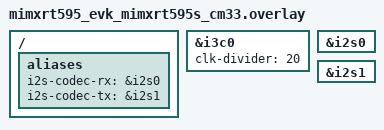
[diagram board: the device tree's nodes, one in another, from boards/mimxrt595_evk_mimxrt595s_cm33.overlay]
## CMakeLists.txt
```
# SPDX-License-Identifier: Apache-2.0

cmake_minimum_required(VERSION 3.20.0)

find_package(Zephyr REQUIRED HINTS $ENV{ZEPHYR_BASE})
project(midi_synth)

target_sources(app PRIVATE src/main.c)
```

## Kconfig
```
# Copyright (c) 2025 NXP
# SPDX-License-Identifier: Apache-2.0

source "Kconfig.zephyr"

config I2S_INIT_BUFFERS
	int "Initial count of audio data blocks"
	default 2
	help
	  Controls the initial count of audio data blocks, which are (optionally)
	  filled by data from the DMIC peripheral and played back by the I2S
	  output peripheral.

config SAMPLE_FREQ
	int "Sample rate"
	default 48000
	help
	  Sample frequency of the system.
```

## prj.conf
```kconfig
CONFIG_I2S=y
CONFIG_AUDIO=y
CONFIG_AUDIO_DMIC=n
```

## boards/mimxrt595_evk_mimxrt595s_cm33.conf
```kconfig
#
# Copyright 2024 NXP
#
# SPDX-License-Identifier: Apache-2.0
#

CONFIG_DMA=y
CONFIG_I2S_MCUX_FLEXCOMM=y
CONFIG_I3C=y
CONFIG_HEAP_MEM_POOL_SIZE=81920
CONFIG_AUDIO=y
CONFIG_AUDIO_CODEC=y
CONFIG_AUDIO_CODEC_WM8904=y
CONFIG_I2S_INIT_BUFFERS=4
CONFIG_SAMPLE_FREQ=16000
CONFIG_MAIN_STACK_SIZE=81920
```

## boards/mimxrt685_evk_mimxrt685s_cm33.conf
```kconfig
#
# Copyright 2024 NXP
#
# SPDX-License-Identifier: Apache-2.0
#

CONFIG_DMA=y
CONFIG_I2S_MCUX_FLEXCOMM=y
CONFIG_I3C=y
CONFIG_HEAP_MEM_POOL_SIZE=81920
CONFIG_AUDIO=y
CONFIG_AUDIO_CODEC=y
CONFIG_AUDIO_CODEC_WM8904=y
CONFIG_I2S_INIT_BUFFERS=4
CONFIG_SAMPLE_FREQ=16000
```

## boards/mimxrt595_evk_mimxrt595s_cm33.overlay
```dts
/ {
	aliases {
		i2s-codec-rx = &i2s0;
		i2s-codec-tx = &i2s1;
	};
};

&i3c0 {
	clk-divider = <20>;

	status = "okay";
};

&i2s0 {
	status = "okay";
};

&i2s1 {
	status = "okay";
};
```

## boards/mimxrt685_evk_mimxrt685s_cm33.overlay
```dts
/ {
	aliases {
		i2s-codec-rx = &i2s0;
		i2s-codec-tx = &i2s1;
	};
};

&i3c0 {
	status = "okay";
};

&i2s0 {
	status = "okay";
};

&i2s1 {
	status = "okay";
};
```

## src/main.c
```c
/*
 * Copyright 2025 NXP
 *
 * SPDX-License-Identifier: Apache-2.0
 */

#include <zephyr/kernel.h>
#include <zephyr/sys/printk.h>
#include <zephyr/drivers/i2s.h>
#include <zephyr/audio/codec.h>
#include <string.h>
#include <math.h>
#include <stdint.h>

#include "sine.h"

#ifndef M_PI
#define M_PI 3.14159265358979323846
#endif

#define I2S_CODEC_TX DT_ALIAS(i2s_codec_tx)

#define SAMPLE_FREQUENCY CONFIG_SAMPLE_FREQ
#define SAMPLE_BIT_WIDTH (16U)
#define BYTES_PER_SAMPLE sizeof(int16_t)
#define NUMBER_OF_CHANNELS (2U)
/* Such block length provides an echo with the delay of 100 ms. */
#define SAMPLES_PER_BLOCK ((SAMPLE_FREQUENCY / 10) * NUMBER_OF_CHANNELS)
#define INITIAL_BLOCKS    CONFIG_I2S_INIT_BUFFERS
#define TIMEOUT           (2000U)

#define BLOCK_SIZE  (BYTES_PER_SAMPLE * SAMPLES_PER_BLOCK)
#define BLOCK_COUNT (INITIAL_BLOCKS + 32)
K_MEM_SLAB_DEFINE_STATIC(mem_slab, BLOCK_SIZE, BLOCK_COUNT, 4);

static bool configure_tx_streams(const struct device *i2s_dev, struct i2s_config *config)
{
	int ret;

	ret = i2s_configure(i2s_dev, I2S_DIR_TX, config);
	if (ret < 0) {
		printk("Failed to configure codec stream: %d\n", ret);
		return false;
	}

	return true;
}

static bool trigger_command(const struct device *i2s_dev_codec, enum i2s_trigger_cmd cmd)
{
	int ret;

	ret = i2s_trigger(i2s_dev_codec, I2S_DIR_TX, cmd);
	if (ret < 0) {
		printk("Failed to trigger command %d on TX: %d\n", cmd, ret);
		return false;
	}

	return true;
}

int main(void)
{
	const struct device *const i2s_dev_codec = DEVICE_DT_GET(I2S_CODEC_TX);
	const struct device *const codec_dev = DEVICE_DT_GET(DT_NODELABEL(audio_codec));
	struct i2s_config config;
	struct audio_codec_cfg audio_cfg;
	int ret = 0;

	printk("MIDI Synth sample\n");

	if (!device_is_ready(i2s_dev_codec)) {
		printk("%s is not ready\n", i2s_dev_codec->name);
		return 0;
	}

	if (!device_is_ready(codec_dev)) {
		printk("%s is not ready", codec_dev->name);
		return 0;
	}
	audio_cfg.dai_route = AUDIO_ROUTE_PLAYBACK;
	audio_cfg.dai_type = AUDIO_DAI_TYPE_I2S;
	audio_cfg.dai_cfg.i2s.word_size = SAMPLE_BIT_WIDTH;
	audio_cfg.dai_cfg.i2s.channels = 2;
	audio_cfg.dai_cfg.i2s.format = I2S_FMT_DATA_FORMAT_I2S;
	audio_cfg.dai_cfg.i2s.options = I2S_OPT_FRAME_CLK_MASTER;
	audio_cfg.dai_cfg.i2s.frame_clk_freq = SAMPLE_FREQUENCY;
	audio_cfg.dai_cfg.i2s.mem_slab = &mem_slab;
	audio_cfg.dai_cfg.i2s.block_size = BLOCK_SIZE;
	audio_codec_configure(codec_dev, &audio_cfg);
	k_msleep(1000);

	config.word_size = SAMPLE_BIT_WIDTH;
	config.channels = NUMBER_OF_CHANNELS;
	config.format = I2S_FMT_DATA_FORMAT_I2S;
	config.options = I2S_OPT_BIT_CLK_MASTER | I2S_OPT_FRAME_CLK_MASTER;
	config.frame_clk_freq = SAMPLE_FREQUENCY;
	config.mem_slab = &mem_slab;
	config.block_size = BLOCK_SIZE;
	config.timeout = TIMEOUT;
	if (!configure_tx_streams(i2s_dev_codec, &config)) {
		printk("failure to config streams\n");
		return 0;
	}

	printk("start streams\n");
	for (;;) {
		bool started = false;

		while (1) {
			double duration = 0.1;
			double amplitude = 1.0;
			double phase = 0.0;
			double phase_increment = 2 * M_PI * 440 / SAMPLE_FREQUENCY;

			uint32_t buflen = SAMPLE_FREQUENCY * duration;
			uint16_t sine_buf[buflen * 2];

			for(uint32_t i = 0; i < buflen * 2; i+=2)
			{
				sine_buf[i] = amplitude * 32767 * ((sin(phase) + 1) / 2);
				sine_buf[i + 1] = sine_buf[i];

				phase += phase_increment;

				if (phase >= 2 * M_PI) phase -= 2 * M_PI;
			}

			ret = i2s_buf_write(i2s_dev_codec, (void*)&sine_buf, buflen * 2);

			if (ret < 0) {
				printk("Failed to write data: %d\n", ret);
				break;
			}
			if (ret < 0) {
				printk("error %d\n", ret);
				break;
			}
			if (!started) {
				i2s_trigger(i2s_dev_codec, I2S_DIR_TX, I2S_TRIGGER_START);
				started = true;
			}
		}
		if (!trigger_command(i2s_dev_codec, I2S_TRIGGER_DROP)) {
			printk("Send I2S trigger DRAIN failed: %d", ret);
			return 0;
		}

		printk("Streams stopped\n");
		return 0;
	}
}
```
